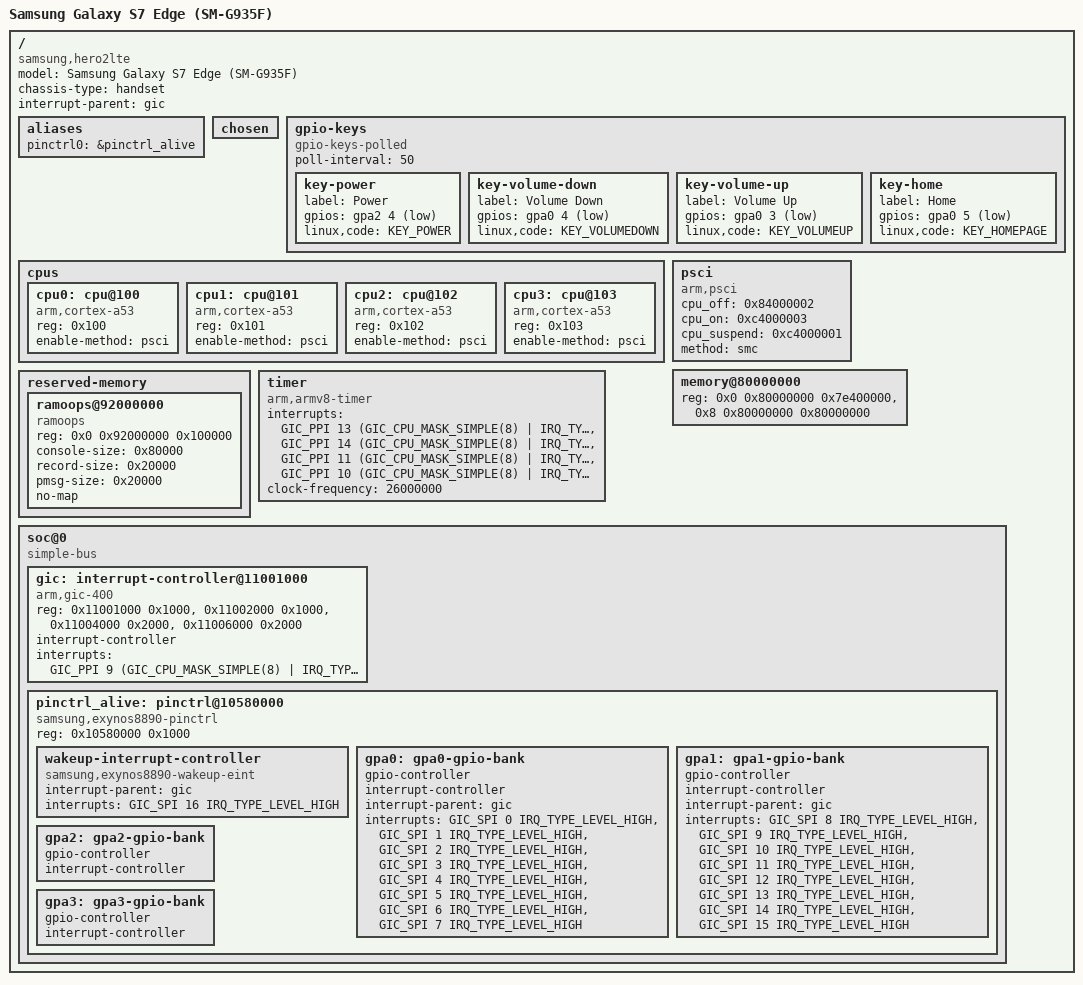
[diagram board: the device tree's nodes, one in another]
// SPDX-License-Identifier: GPL-2.0 OR BSD-3-Clause
/*
 * Samsung Galaxy S7 Edge (hero2lte / SM-G935F), minimal DT for booting
 * mainline Linux through Mu-Silicium UEFI (EFI stub, efifb console).
 *
 * CPU, GIC, timer and PSCI nodes follow Ivaylo Ivanov's exynos8890.dtsi
 * (v1 series, Sep 2025). Memory and the frame buffer come from UEFI.
 */
/dts-v1/;
#include <dt-bindings/interrupt-controller/arm-gic.h>
#include <dt-bindings/gpio/gpio.h>
#include <dt-bindings/input/input.h>

/ {
	model = "Samsung Galaxy S7 Edge (SM-G935F)";
	compatible = "samsung,hero2lte", "samsung,exynos8890";
	chassis-type = "handset";
	interrupt-parent = <&gic>;
	#address-cells = <2>;
	#size-cells = <1>;

	aliases {
		pinctrl0 = &pinctrl_alive;
	};

	chosen { };

	/* Polled: no CMU/EINT setup needed, S-Boot leaves the pins as inputs */
	gpio-keys {
		compatible = "gpio-keys-polled";
		poll-interval = <50>;

		key-power {
			label = "Power";
			gpios = <&gpa2 4 GPIO_ACTIVE_LOW>;
			linux,code = <KEY_POWER>;
		};

		key-volume-down {
			label = "Volume Down";
			gpios = <&gpa0 4 GPIO_ACTIVE_LOW>;
			linux,code = <KEY_VOLUMEDOWN>;
		};

		key-volume-up {
			label = "Volume Up";
			gpios = <&gpa0 3 GPIO_ACTIVE_LOW>;
			linux,code = <KEY_VOLUMEUP>;
		};

		key-home {
			label = "Home";
			gpios = <&gpa0 5 GPIO_ACTIVE_LOW>;
			linux,code = <KEY_HOMEPAGE>;
		};
	};

	cpus {
		#address-cells = <1>;
		#size-cells = <0>;

		/* Only the Cortex-A53 cluster: Mongoose M1 cores have a TLB conflict errata */
		cpu0: cpu@100 { device_type = "cpu"; compatible = "arm,cortex-a53"; reg = <0x100>; enable-method = "psci"; };
		cpu1: cpu@101 { device_type = "cpu"; compatible = "arm,cortex-a53"; reg = <0x101>; enable-method = "psci"; };
		cpu2: cpu@102 { device_type = "cpu"; compatible = "arm,cortex-a53"; reg = <0x102>; enable-method = "psci"; };
		cpu3: cpu@103 { device_type = "cpu"; compatible = "arm,cortex-a53"; reg = <0x103>; enable-method = "psci"; };
	};

	psci {
		compatible = "arm,psci";
		cpu_off = <0x84000002>;
		cpu_on = <0xc4000003>;
		cpu_suspend = <0xc4000001>;
		method = "smc";
	};

	memory@80000000 {
		device_type = "memory";
		reg = <0x0 0x80000000 0x7e400000>,
		      <0x8 0x80000000 0x80000000>;
	};

	reserved-memory {
		#address-cells = <2>;
		#size-cells = <1>;
		ranges;

		/* exynos-snapshot log_pstore area, readable later from TWRP */
		ramoops@92000000 {
			compatible = "ramoops";
			reg = <0x0 0x92000000 0x100000>;
			console-size = <0x80000>;
			record-size = <0x20000>;
			pmsg-size = <0x20000>;
			no-map;
		};
	};

	timer {
		compatible = "arm,armv8-timer";
		interrupts = <GIC_PPI 13 (GIC_CPU_MASK_SIMPLE(8) | IRQ_TYPE_LEVEL_LOW)>,
			     <GIC_PPI 14 (GIC_CPU_MASK_SIMPLE(8) | IRQ_TYPE_LEVEL_LOW)>,
			     <GIC_PPI 11 (GIC_CPU_MASK_SIMPLE(8) | IRQ_TYPE_LEVEL_LOW)>,
			     <GIC_PPI 10 (GIC_CPU_MASK_SIMPLE(8) | IRQ_TYPE_LEVEL_LOW)>;
		/* S-Boot leaves CNTFRQ_EL0 empty */
		clock-frequency = <26000000>;
	};

	soc@0 {
		compatible = "simple-bus";
		ranges = <0x0 0x0 0x0 0x20000000>;
		#address-cells = <1>;
		#size-cells = <1>;

		gic: interrupt-controller@11001000 {
			compatible = "arm,gic-400";
			reg = <0x11001000 0x1000>,
			      <0x11002000 0x1000>,
			      <0x11004000 0x2000>,
			      <0x11006000 0x2000>;
			#interrupt-cells = <3>;
			interrupt-controller;
			interrupts = <GIC_PPI 9 (GIC_CPU_MASK_SIMPLE(8) | IRQ_TYPE_LEVEL_HIGH)>;
			#address-cells = <0>;
		};

		/* Bank layout from Ivaylo Ivanov's exynos8890-pinctrl.dtsi; pclk left to S-Boot */
		pinctrl_alive: pinctrl@10580000 {
			compatible = "samsung,exynos8890-pinctrl";
			reg = <0x10580000 0x1000>;

			wakeup-interrupt-controller {
				compatible = "samsung,exynos8890-wakeup-eint",
					     "samsung,exynos7-wakeup-eint";
				interrupt-parent = <&gic>;
				interrupts = <GIC_SPI 16 IRQ_TYPE_LEVEL_HIGH>;
			};

			gpa0: gpa0-gpio-bank {
				gpio-controller;
				#gpio-cells = <2>;
				interrupt-controller;
				#interrupt-cells = <2>;
				interrupt-parent = <&gic>;
				interrupts = <GIC_SPI 0 IRQ_TYPE_LEVEL_HIGH>, <GIC_SPI 1 IRQ_TYPE_LEVEL_HIGH>,
					     <GIC_SPI 2 IRQ_TYPE_LEVEL_HIGH>, <GIC_SPI 3 IRQ_TYPE_LEVEL_HIGH>,
					     <GIC_SPI 4 IRQ_TYPE_LEVEL_HIGH>, <GIC_SPI 5 IRQ_TYPE_LEVEL_HIGH>,
					     <GIC_SPI 6 IRQ_TYPE_LEVEL_HIGH>, <GIC_SPI 7 IRQ_TYPE_LEVEL_HIGH>;
			};

			gpa1: gpa1-gpio-bank {
				gpio-controller;
				#gpio-cells = <2>;
				interrupt-controller;
				#interrupt-cells = <2>;
				interrupt-parent = <&gic>;
				interrupts = <GIC_SPI 8 IRQ_TYPE_LEVEL_HIGH>, <GIC_SPI 9 IRQ_TYPE_LEVEL_HIGH>,
					     <GIC_SPI 10 IRQ_TYPE_LEVEL_HIGH>, <GIC_SPI 11 IRQ_TYPE_LEVEL_HIGH>,
					     <GIC_SPI 12 IRQ_TYPE_LEVEL_HIGH>, <GIC_SPI 13 IRQ_TYPE_LEVEL_HIGH>,
					     <GIC_SPI 14 IRQ_TYPE_LEVEL_HIGH>, <GIC_SPI 15 IRQ_TYPE_LEVEL_HIGH>;
			};

			gpa2: gpa2-gpio-bank {
				gpio-controller;
				#gpio-cells = <2>;
				interrupt-controller;
				#interrupt-cells = <2>;
			};

			gpa3: gpa3-gpio-bank {
				gpio-controller;
				#gpio-cells = <2>;
				interrupt-controller;
				#interrupt-cells = <2>;
			};
		};
	};
};
